VERSION ""

NS_ :

BS_:

BU_: Node Kiosk

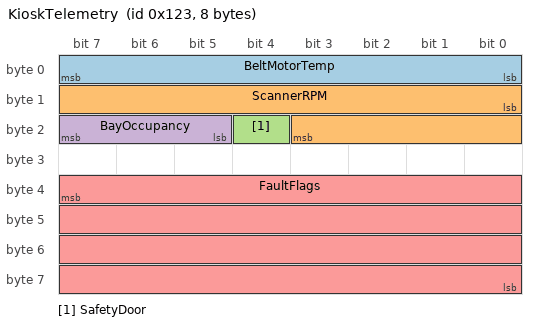
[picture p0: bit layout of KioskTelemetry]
BO_ 291 KioskTelemetry: 8 Kiosk
 SG_ BeltMotorTemp : 0|8@1+ (0.5,20) [20|147.5] "C" Node
 SG_ ScannerRPM : 8|12@1+ (10,0) [0|40950] "RPM" Node
 SG_ SafetyDoor : 20|1@1+ (1,0) [0|1] "bool" Node
 SG_ BayOccupancy : 21|3@1+ (1,0) [0|7] "count" Node
 SG_ FaultFlags : 39|32@0+ (1,0) [0|4294967295] "bitmask" Node

CM_ BO_ 291 "Kiosk Device Telemetry Frame";
CM_ SG_ 291 BeltMotorTemp "Belt Motor Temperature in Celsius";
CM_ SG_ 291 ScannerRPM "Optical Scanner Speed in RPM";
CM_ SG_ 291 SafetyDoor "0=Open, 1=Closed";
CM_ SG_ 291 BayOccupancy "Number of occupied book bays";
CM_ SG_ 291 FaultFlags "32-bit hardware fault bitmask";
